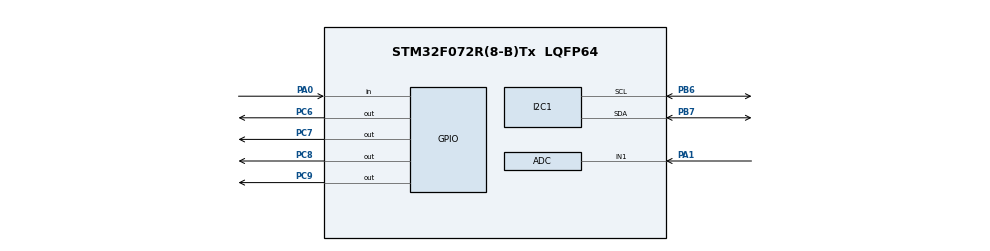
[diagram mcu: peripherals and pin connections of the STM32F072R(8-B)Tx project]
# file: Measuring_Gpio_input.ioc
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Mcu.Family=STM32F0
Mcu.Name=STM32F072R(8-B)Tx
Mcu.Package=LQFP64
NVIC.TIM2_IRQn=true\:0\:0\:false\:false\:true\:true
NVIC.TIM6_DAC_IRQn=true\:0\:0\:false\:false\:true\:true
PA0.Signal=GPIO_Input
PA1.Mode=IN1
PA1.Signal=ADC_IN1
PB6.Mode=I2C
PB6.Signal=I2C1_SCL
PB7.Mode=I2C
PB7.Signal=I2C1_SDA
PC6.Signal=GPIO_Output
PC7.Signal=GPIO_Output
PC8.Signal=GPIO_Output
PC9.Signal=GPIO_Output
ProjectManager.HeapSize=0x200
ProjectManager.StackSize=0x400
ProjectManager.TargetToolchain=MDK-ARM V5
TIM2.Period=100
TIM2.Prescaler=799
TIM6.AutoReloadPreload=TIM_AUTORELOAD_PRELOAD_DISABLE
TIM6.Period=10
TIM6.Prescaler=7999
TIM6.TIM_MasterOutputTrigger=TIM_TRGO_UPDATE
VP_TIM2_VS_ClockSourceINT.Mode=Internal
VP_TIM6_VS_ClockSourceINT.Mode=Enable_Timer
board=Measuring_Gpio_input

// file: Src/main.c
/**
  ******************************************************************************
  * @file           : main.c
  * @brief          : Main program body
  ******************************************************************************
  ** This notice applies to any and all portions of this file
  * that are not between comment pairs USER CODE BEGIN and
  * USER CODE END. Other portions of this file, whether
  * inserted by the user or by software development tools
  * are owned by their respective copyright owners.
  *
  * COPYRIGHT(c) 2018 STMicroelectronics
  *
  * Redistribution and use in source and binary forms, with or without modification,
  * are permitted provided that the following conditions are met:
  *   1. Redistributions of source code must retain the above copyright notice,
  *      this list of conditions and the following disclaimer.
  *   2. Redistributions in binary form must reproduce the above copyright notice,
  *      this list of conditions and the following disclaimer in the documentation
  *      and/or other materials provided with the distribution.
  *   3. Neither the name of STMicroelectronics nor the names of its contributors
  *      may be used to endorse or promote products derived from this software
  *      without specific prior written permission.
  *
  * THIS SOFTWARE IS PROVIDED BY THE COPYRIGHT HOLDERS AND CONTRIBUTORS "AS IS"
  * AND ANY EXPRESS OR IMPLIED WARRANTIES, INCLUDING, BUT NOT LIMITED TO, THE
  * IMPLIED WARRANTIES OF MERCHANTABILITY AND FITNESS FOR A PARTICULAR PURPOSE ARE
  * DISCLAIMED. IN NO EVENT SHALL THE COPYRIGHT HOLDER OR CONTRIBUTORS BE LIABLE
  * FOR ANY DIRECT, INDIRECT, INCIDENTAL, SPECIAL, EXEMPLARY, OR CONSEQUENTIAL
  * DAMAGES (INCLUDING, BUT NOT LIMITED TO, PROCUREMENT OF SUBSTITUTE GOODS OR
  * SERVICES; LOSS OF USE, DATA, OR PROFITS; OR BUSINESS INTERRUPTION) HOWEVER
  * CAUSED AND ON ANY THEORY OF LIABILITY, WHETHER IN CONTRACT, STRICT LIABILITY,
  * OR TORT (INCLUDING NEGLIGENCE OR OTHERWISE) ARISING IN ANY WAY OUT OF THE USE
  * OF THIS SOFTWARE, EVEN IF ADVISED OF THE POSSIBILITY OF SUCH DAMAGE.
  *
  ******************************************************************************
  */
#include "main.h"
#include "stm32f0xx_hal.h"

/* USER CODE BEGIN Includes */
#include "lcd.h"

/* USER CODE END Includes */

ADC_HandleTypeDef hadc;

I2C_HandleTypeDef hi2c1;

TIM_HandleTypeDef htim2;
TIM_HandleTypeDef htim6;

/* USER CODE BEGIN PV */
/* Private variables ---------------------------------------------------------*/
uint16_t chetP=0;
uint16_t chetM=0;
uint16_t cut=0;

/* USER CODE END PV */

void SystemClock_Config(void);
static void MX_GPIO_Init(void);
static void MX_TIM2_Init(void);
static void MX_I2C1_Init(void);
static void MX_ADC_Init(void);
static void MX_TIM6_Init(void);

/* USER CODE BEGIN PFP */
/* Private function prototypes -----------------------------------------------*/

/* USER CODE END PFP */

int main(void)
{

  /* MCU Configuration----------------------------------------------------------*/

  /* Reset of all peripherals, Initializes the Flash interface and the Systick. */
  HAL_Init();

  /* Configure the system clock */
  SystemClock_Config();

  /* Initialize all configured peripherals */
  MX_GPIO_Init();
  MX_TIM2_Init();
  MX_I2C1_Init();
  MX_ADC_Init();
  MX_TIM6_Init();
  /* USER CODE BEGIN 2 */
HAL_TIM_Base_Start_IT (&htim6);

lcd_init;
lcd_xy(0,0);
lcd_put_string("Gpio measure");
  /* USER CODE END 2 */

  /* Infinite loop */
  while (1)
  {

  /* USER CODE BEGIN 3 */

		if(chetM>=300)
		{
			HAL_GPIO_WritePin(GPIOC,GPIO_PIN_7,GPIO_PIN_RESET);
  chetP=0;
		}
	if (chetP==50)
	{
		HAL_GPIO_WritePin(GPIOC,GPIO_PIN_7,GPIO_PIN_SET);
 chetM=0;
	}
	/*--------------Rezim Cut -+ ------------*/
// if (chetP>10)
//	{
//	cut+=chetP;
//	}
//	if (chetM>100 && HAL_GPIO_ReadPin(GPIOC,GPIO_PIN_0)==0)
//	{
//	cut=0;
//	chetP=0;
//	}
	/*------------------------------------*/
	/* USER CODE END 3 */
}
}

void SystemClock_Config(void)
{

  RCC_OscInitTypeDef RCC_OscInitStruct;
  RCC_ClkInitTypeDef RCC_ClkInitStruct;
  RCC_PeriphCLKInitTypeDef PeriphClkInit;

    /**Initializes the CPU, AHB and APB busses clocks
    */
  RCC_OscInitStruct.OscillatorType = RCC_OSCILLATORTYPE_HSI|RCC_OSCILLATORTYPE_HSI14;
  RCC_OscInitStruct.HSIState = RCC_HSI_ON;
  RCC_OscInitStruct.HSI14State = RCC_HSI14_ON;
  RCC_OscInitStruct.HSICalibrationValue = 16;
  RCC_OscInitStruct.HSI14CalibrationValue = 16;
  RCC_OscInitStruct.PLL.PLLState = RCC_PLL_NONE;
  if (HAL_RCC_OscConfig(&RCC_OscInitStruct) != HAL_OK)
  {
    _Error_Handler(__FILE__, __LINE__);
  }

    /**Initializes the CPU, AHB and APB busses clocks
    */
  RCC_ClkInitStruct.ClockType = RCC_CLOCKTYPE_HCLK|RCC_CLOCKTYPE_SYSCLK
                              |RCC_CLOCKTYPE_PCLK1;
  RCC_ClkInitStruct.SYSCLKSource = RCC_SYSCLKSOURCE_HSI;
  RCC_ClkInitStruct.AHBCLKDivider = RCC_SYSCLK_DIV1;
  RCC_ClkInitStruct.APB1CLKDivider = RCC_HCLK_DIV1;

  if (HAL_RCC_ClockConfig(&RCC_ClkInitStruct, FLASH_LATENCY_0) != HAL_OK)
  {
    _Error_Handler(__FILE__, __LINE__);
  }

  PeriphClkInit.PeriphClockSelection = RCC_PERIPHCLK_I2C1;
  PeriphClkInit.I2c1ClockSelection = RCC_I2C1CLKSOURCE_HSI;
  if (HAL_RCCEx_PeriphCLKConfig(&PeriphClkInit) != HAL_OK)
  {
    _Error_Handler(__FILE__, __LINE__);
  }

    /**Configure the Systick interrupt time
    */
  HAL_SYSTICK_Config(HAL_RCC_GetHCLKFreq()/1000);

    /**Configure the Systick
    */
  HAL_SYSTICK_CLKSourceConfig(SYSTICK_CLKSOURCE_HCLK);

  /* SysTick_IRQn interrupt configuration */
  HAL_NVIC_SetPriority(SysTick_IRQn, 0, 0);
}

/* ADC init function */
static void MX_ADC_Init(void)
{

  ADC_ChannelConfTypeDef sConfig;

    /**Configure the global features of the ADC (Clock, Resolution, Data Alignment and number of conversion)
    */
  hadc.Instance = ADC1;
  hadc.Init.ClockPrescaler = ADC_CLOCK_ASYNC_DIV1;
  hadc.Init.Resolution = ADC_RESOLUTION_12B;
  hadc.Init.DataAlign = ADC_DATAALIGN_RIGHT;
  hadc.Init.ScanConvMode = ADC_SCAN_DIRECTION_FORWARD;
  hadc.Init.EOCSelection = ADC_EOC_SINGLE_CONV;
  hadc.Init.LowPowerAutoWait = DISABLE;
  hadc.Init.LowPowerAutoPowerOff = DISABLE;
  hadc.Init.ContinuousConvMode = DISABLE;
  hadc.Init.DiscontinuousConvMode = DISABLE;
  hadc.Init.ExternalTrigConv = ADC_SOFTWARE_START;
  hadc.Init.ExternalTrigConvEdge = ADC_EXTERNALTRIGCONVEDGE_NONE;
  hadc.Init.DMAContinuousRequests = DISABLE;
  hadc.Init.Overrun = ADC_OVR_DATA_PRESERVED;
  if (HAL_ADC_Init(&hadc) != HAL_OK)
  {
    _Error_Handler(__FILE__, __LINE__);
  }

    /**Configure for the selected ADC regular channel to be converted.
    */
  sConfig.Channel = ADC_CHANNEL_1;
  sConfig.Rank = ADC_RANK_CHANNEL_NUMBER;
  sConfig.SamplingTime = ADC_SAMPLETIME_1CYCLE_5;
  if (HAL_ADC_ConfigChannel(&hadc, &sConfig) != HAL_OK)
  {
    _Error_Handler(__FILE__, __LINE__);
  }

}

/* I2C1 init function */
static void MX_I2C1_Init(void)
{

  hi2c1.Instance = I2C1;
  hi2c1.Init.Timing = 0x2000090E;
  hi2c1.Init.OwnAddress1 = 0;
  hi2c1.Init.AddressingMode = I2C_ADDRESSINGMODE_7BIT;
  hi2c1.Init.DualAddressMode = I2C_DUALADDRESS_DISABLE;
  hi2c1.Init.OwnAddress2 = 0;
  hi2c1.Init.OwnAddress2Masks = I2C_OA2_NOMASK;
  hi2c1.Init.GeneralCallMode = I2C_GENERALCALL_DISABLE;
  hi2c1.Init.NoStretchMode = I2C_NOSTRETCH_DISABLE;
  if (HAL_I2C_Init(&hi2c1) != HAL_OK)
  {
    _Error_Handler(__FILE__, __LINE__);
  }

    /**Configure Analogue filter
    */
  if (HAL_I2CEx_ConfigAnalogFilter(&hi2c1, I2C_ANALOGFILTER_ENABLE) != HAL_OK)
  {
    _Error_Handler(__FILE__, __LINE__);
  }

    /**Configure Digital filter
    */
  if (HAL_I2CEx_ConfigDigitalFilter(&hi2c1, 0) != HAL_OK)
  {
    _Error_Handler(__FILE__, __LINE__);
  }

}

/* TIM2 init function */
static void MX_TIM2_Init(void)
{

  TIM_ClockConfigTypeDef sClockSourceConfig;
  TIM_MasterConfigTypeDef sMasterConfig;

  htim2.Instance = TIM2;
  htim2.Init.Prescaler = 799;
  htim2.Init.CounterMode = TIM_COUNTERMODE_UP;
  htim2.Init.Period = 100;
  htim2.Init.ClockDivision = TIM_CLOCKDIVISION_DIV1;
  htim2.Init.AutoReloadPreload = TIM_AUTORELOAD_PRELOAD_DISABLE;
  if (HAL_TIM_Base_Init(&htim2) != HAL_OK)
  {
    _Error_Handler(__FILE__, __LINE__);
  }

  sClockSourceConfig.ClockSource = TIM_CLOCKSOURCE_INTERNAL;
  if (HAL_TIM_ConfigClockSource(&htim2, &sClockSourceConfig) != HAL_OK)
  {
    _Error_Handler(__FILE__, __LINE__);
  }

  sMasterConfig.MasterOutputTrigger = TIM_TRGO_RESET;
  sMasterConfig.MasterSlaveMode = TIM_MASTERSLAVEMODE_DISABLE;
  if (HAL_TIMEx_MasterConfigSynchronization(&htim2, &sMasterConfig) != HAL_OK)
  {
    _Error_Handler(__FILE__, __LINE__);
  }

}

/* TIM6 init function */
static void MX_TIM6_Init(void)
{

  TIM_MasterConfigTypeDef sMasterConfig;

  htim6.Instance = TIM6;
  htim6.Init.Prescaler = 799;
  htim6.Init.CounterMode = TIM_COUNTERMODE_UP;
  htim6.Init.Period = 10;
  htim6.Init.AutoReloadPreload = TIM_AUTORELOAD_PRELOAD_DISABLE;
  if (HAL_TIM_Base_Init(&htim6) != HAL_OK)
  {
    _Error_Handler(__FILE__, __LINE__);
  }

  sMasterConfig.MasterOutputTrigger = TIM_TRGO_UPDATE;
  sMasterConfig.MasterSlaveMode = TIM_MASTERSLAVEMODE_DISABLE;
  if (HAL_TIMEx_MasterConfigSynchronization(&htim6, &sMasterConfig) != HAL_OK)
  {
    _Error_Handler(__FILE__, __LINE__);
  }

}

/** Configure pins as
        * Analog
        * Input
        * Output
        * EVENT_OUT
        * EXTI
*/
static void MX_GPIO_Init(void)
{

  GPIO_InitTypeDef GPIO_InitStruct;

  /* GPIO Ports Clock Enable */
  __HAL_RCC_GPIOA_CLK_ENABLE();
  __HAL_RCC_GPIOC_CLK_ENABLE();
  __HAL_RCC_GPIOB_CLK_ENABLE();

  /*Configure GPIO pin Output Level */
  HAL_GPIO_WritePin(GPIOC, GPIO_PIN_6|GPIO_PIN_7|GPIO_PIN_8|GPIO_PIN_9, GPIO_PIN_RESET);

  /*Configure GPIO pin : PA0 */
  GPIO_InitStruct.Pin = GPIO_PIN_0;
  GPIO_InitStruct.Mode = GPIO_MODE_INPUT;
  GPIO_InitStruct.Pull = GPIO_NOPULL;
  HAL_GPIO_Init(GPIOA, &GPIO_InitStruct);

  /*Configure GPIO pins : PC6 PC7 PC8 PC9 */
  GPIO_InitStruct.Pin = GPIO_PIN_6|GPIO_PIN_7|GPIO_PIN_8|GPIO_PIN_9;
  GPIO_InitStruct.Mode = GPIO_MODE_OUTPUT_PP;
  GPIO_InitStruct.Pull = GPIO_NOPULL;
  GPIO_InitStruct.Speed = GPIO_SPEED_FREQ_LOW;
  HAL_GPIO_Init(GPIOC, &GPIO_InitStruct);

}

void _Error_Handler(char *file, int line)
{
  while(1)
  {
  }
}

/************************ (C) COPYRIGHT STMicroelectronics *****END OF FILE****/
